AUTOSAR XML (schema 00046)
package /ComponentTypes
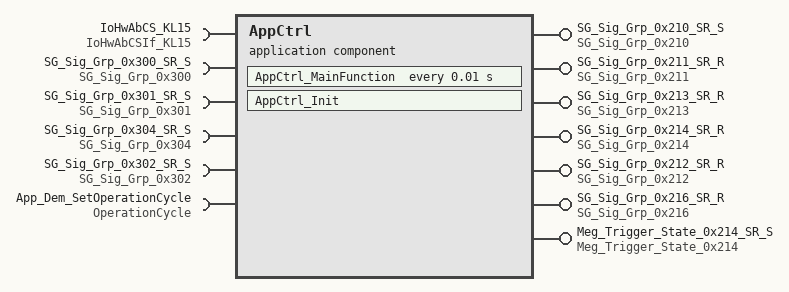
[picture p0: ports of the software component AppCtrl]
  application sw component type AppCtrl
    5 x require port:
      IoHwAbCS_KL15: client-com-spec=IoHwAbOp_KL15_Read, required-interface=IoHwAbCSIf_KL15
      SG_Sig_Grp_0x300_SR_S: nonqueued-receiver-com-spec{data-element=SG_Sig_Grp_0x300, filter=data-filter-type=ALWAYS, init-value=fields=[D_Led1_Control:2, D_Led2_Control:2, D_Led3_Control:2, D_Led4_Control:2, SupD_Checksum_0x300:0, SupD_Counter_0x300:0]}, required-interface=SG_Sig_Grp_0x300
      SG_Sig_Grp_0x301_SR_S: nonqueued-receiver-com-spec{data-element=SG_Sig_Grp_0x301, filter=data-filter-type=ALWAYS, init-value=fields=[D_Button1_Control:0, D_Button2_Control:0, D_Button3_Control:0, D_Button4_Control:0]}, required-interface=SG_Sig_Grp_0x301
      SG_Sig_Grp_0x304_SR_S: nonqueued-receiver-com-spec{data-element=SG_Sig_Grp_0x304, filter=data-filter-type=ALWAYS, init-value=fields=[D_Led1_CtrlMode:0, D_Led2_CtrlMode:0, D_Led3_CtrlMode:0, D_Led4_CtrlMode:0, SupD_Checksum_0x304:0, SupD_Counter_0x304:0]}, required-interface=SG_Sig_Grp_0x304
      SG_Sig_Grp_0x302_SR_S: nonqueued-receiver-com-spec{data-element=SG_Sig_Grp_0x302, filter=data-filter-type=ALWAYS, init-value=fields=[E_Sig_0x302_Used_1:0, E_Sig_0x302_Used_2:0, E_Sig_0x302_Used_3:0]}, required-interface=SG_Sig_Grp_0x302
    7 x provide port:
      SG_Sig_Grp_0x210_SR_S: nonqueued-sender-com-spec{data-element=SG_Sig_Grp_0x210, init-value=fields=[F_Led1_State:0, F_Led2_State:0, F_Led3_State:0, F_Led4_State:0]}, provided-interface=SG_Sig_Grp_0x210
      SG_Sig_Grp_0x211_SR_R: nonqueued-sender-com-spec{data-element=SG_Sig_Grp_0x211, init-value=fields=[F_Button1_State:0, F_Button2_State:0, F_Button3_State:0, F_Button4_State:0]}, provided-interface=SG_Sig_Grp_0x211
      SG_Sig_Grp_0x213_SR_R: nonqueued-sender-com-spec{data-element=SG_Sig_Grp_0x213, init-value=fields=F_AAA_Angle:36}, provided-interface=SG_Sig_Grp_0x213
      SG_Sig_Grp_0x214_SR_R: nonqueued-sender-com-spec{data-element=SG_Sig_Grp_0x214, init-value=fields=[F_Sig_0x214_Used_1:0, F_Sig_0x214_Used_2:0, F_Sig_0x214_Used_3:0, F_Sig_0x214_Used_5:0]}, provided-interface=SG_Sig_Grp_0x214
      SG_Sig_Grp_0x212_SR_R: nonqueued-sender-com-spec{data-element=SG_Sig_Grp_0x212, init-value=fields=[F_PowerMode:0, SupF_Checksum_0x212:0, SupF_Counter_0x212:0]}, provided-interface=SG_Sig_Grp_0x212
      SG_Sig_Grp_0x216_SR_R: nonqueued-sender-com-spec{data-element=SG_Sig_Grp_0x216, init-value=fields=[F_Meg_E2E_Error:0, F_Mes_Lost_Error:0]}, provided-interface=SG_Sig_Grp_0x216
      Meg_Trigger_State_0x214_SR_S: nonqueued-sender-com-spec{data-element=Meg_Trigger_State, init-value=0}, provided-interface=Meg_Trigger_State_0x214
    require port App_Dem_SetOperationCycle: required-com-specs=[SetOperationCycleState, GetOperationCycleState], required-interface=OperationCycle
    behavior AppCtrl_InternalBehavior
      timing event TMT_AppCtrl_MainFunction: start-on-event=AppCtrl_MainFunction, period=0.01
      init event AppCtrl_InitEvent: start-on-event=AppCtrl_Init
      runnable AppCtrl_MainFunction
        data-receive-point-by-arguments:
          4 x access:
            REC_SG_Sig_Grp_0x{300..302}_SR_S_SG_Sig_Grp_0x{300..302}: accessed-variable=SG_Sig_Grp_0x{300..302}_SR_S.SG_Sig_Grp_0x{300..302}
            REC_SG_Sig_Grp_0x304_SR_S_SG_Sig_Grp_0x304: accessed-variable=SG_Sig_Grp_0x304_SR_S.SG_Sig_Grp_0x304
        data-send-points:
          7 x access:
            SEND_SG_Sig_Grp_0x210_SR_S_SG_Sig_Grp_0x210: accessed-variable=SG_Sig_Grp_0x210_SR_S.SG_Sig_Grp_0x210
            SEND_SG_Sig_Grp_0x{211..214}_SR_R_SG_Sig_Grp_0x{211..214}: accessed-variable=SG_Sig_Grp_0x{211..214}_SR_R.SG_Sig_Grp_0x{211..214}
            SEND_SG_Sig_Grp_0x216_SR_R_SG_Sig_Grp_0x216: accessed-variable=SG_Sig_Grp_0x216_SR_R.SG_Sig_Grp_0x216
            SEND_Meg_Trigger_State_0x214_SR_S_Meg_Trigger_State: accessed-variable=Meg_Trigger_State_0x214_SR_S.Meg_Trigger_State
        sync call SC_IoHwAbCS_KL15_IoHwAbOp_KL15_Read: operation=IoHwAbCS_KL15.IoHwAbOp_KL15_Read
        sync call SC_App_Dem_SetOperationCycle_SetOperationCycleState: operation=App_Dem_SetOperationCycle.SetOperationCycleState
        sync call SC_App_Dem_SetOperationCycle_GetOperationCycleState: operation=App_Dem_SetOperationCycle.GetOperationCycleState
      runnable AppCtrl_Init
  swc implementation AppCtrl_Implementation: behavior=AppCtrl_InternalBehavior
